# MKV10Z7 register map
Vendor: Freescale Semiconductor, Inc.; Series: Kinetis_V; File version: 1.6
CPU: CM0PLUS r0p0, little endian, no MPU, no FPU, VTOR, 2 interrupt priority bits
Registers are 32-bit, read-write, reset 0x0 unless marked. A register's access mark holds for its fields unless they carry their own. Offsets are from the block's base; [hi:lo] are bit positions; {n}, {i} and the like mark numbered series.

## NVIC — Nested Vectored Interrupt Controller
Base 0xE000E100
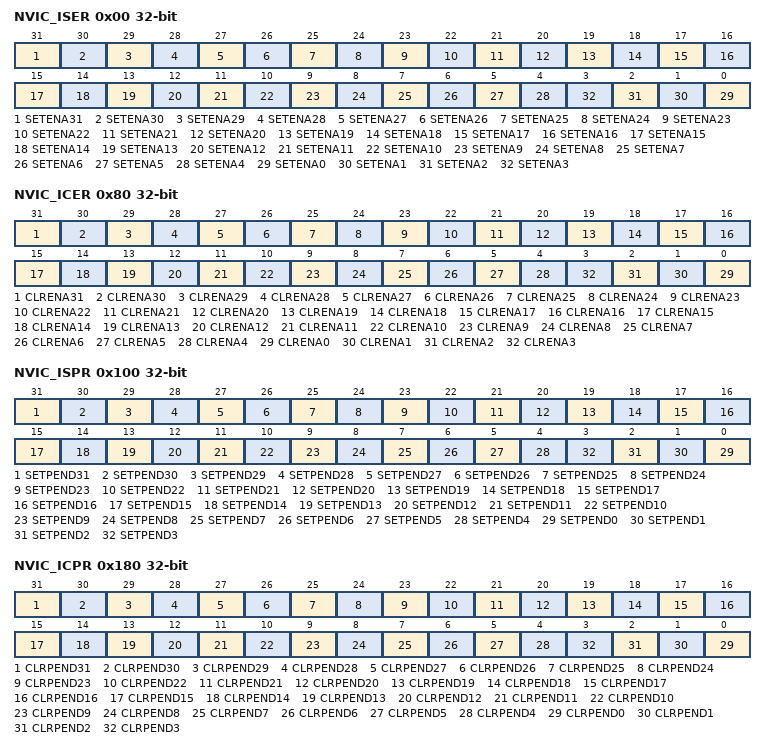
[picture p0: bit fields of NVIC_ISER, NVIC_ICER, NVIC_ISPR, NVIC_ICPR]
0x00 NVIC_ISER — Interrupt Set Enable Register
  [31] SETENA31 — GPIOB, GPIOC, GPIOD and GPIOE Pin detect interrupt set-enable bit
    0=write: no effect; read: GPIOB, GPIOC, GPIOD and GPIOE Pin detect interrupt disabled; 1=write: enable GPIOB, GPIOC, GPIOD and GPIOE Pin detect interrupt; read: GPIOB, GPIOC, GPIOD and GPIOE Pin detect interrupt enabled
  [30] SETENA30 — GPIOA Pin detect interrupt set-enable bit
    0=write: no effect; read: GPIOA Pin detect interrupt disabled; 1=write: enable GPIOA Pin detect interrupt; read: GPIOA Pin detect interrupt enabled
  [29] SETENA29 — Programmable Delay Block interrupt set-enable bit
    0=write: no effect; read: Programmable Delay Block interrupt disabled; 1=write: enable Programmable Delay Block interrupt; read: Programmable Delay Block interrupt enabled
  [28] SETENA28 — Low-Power Timer interrupt set-enable bit
    0=write: no effect; read: Low-Power Timer interrupt disabled; 1=write: enable Low-Power Timer interrupt; read: Low-Power Timer interrupt enabled
  [27] SETENA27 — Multipurpose Clock Generator interrupt set-enable bit
    0=write: no effect; read: Multipurpose Clock Generator interrupt disabled; 1=write: enable Multipurpose Clock Generator interrupt; read: Multipurpose Clock Generator interrupt enabled
  [26] SETENA26 — Reserved iv 42 interrupt set-enable bit
    0=write: no effect; read: Reserved iv 42 interrupt disabled; 1=write: enable Reserved iv 42 interrupt; read: Reserved iv 42 interrupt enabled
  [25] SETENA25 — Digital-to-Analog Converter 0 interrupt set-enable bit
    0=write: no effect; read: Digital-to-Analog Converter 0 interrupt disabled; 1=write: enable Digital-to-Analog Converter 0 interrupt; read: Digital-to-Analog Converter 0 interrupt enabled
  [24] SETENA24 — Reserved iv 40 interrupt set-enable bit
    0=write: no effect; read: Reserved iv 40 interrupt disabled; 1=write: enable Reserved iv 40 interrupt; read: Reserved iv 40 interrupt enabled
  [23] SETENA23 — WDOG and EWM interrupt set-enable bit
    0=write: no effect; read: WDOG and EWM interrupt disabled; 1=write: enable WDOG and EWM interrupt; read: WDOG and EWM interrupt enabled
  [22] SETENA22 — Reserved iv 38 interrupt set-enable bit
    0=write: no effect; read: Reserved iv 38 interrupt disabled; 1=write: enable Reserved iv 38 interrupt; read: Reserved iv 38 interrupt enabled
  [21] SETENA21 — Comparator 1 interrupt set-enable bit
    0=write: no effect; read: Comparator 1 interrupt disabled; 1=write: enable Comparator 1 interrupt; read: Comparator 1 interrupt enabled
  [20] SETENA20 — Comparator 0 interrupt set-enable bit
    0=write: no effect; read: Comparator 0 interrupt disabled; 1=write: enable Comparator 0 interrupt; read: Comparator 0 interrupt enabled
  [19] SETENA19 — FlexTimer Module 2 interrupt set-enable bit
    0=write: no effect; read: FlexTimer Module 2 interrupt disabled; 1=write: enable FlexTimer Module 2 interrupt; read: FlexTimer Module 2 interrupt enabled
  [18] SETENA18 — FlexTimer Module 1 interrupt set-enable bit
    0=write: no effect; read: FlexTimer Module 1 interrupt disabled; 1=write: enable FlexTimer Module 1 interrupt; read: FlexTimer Module 1 interrupt enabled
  [17] SETENA17 — FlexTimer Module 0 interrupt set-enable bit
    0=write: no effect; read: FlexTimer Module 0 interrupt disabled; 1=write: enable FlexTimer Module 0 interrupt; read: FlexTimer Module 0 interrupt enabled
  [16] SETENA16 — Analog-to-Digital Converter 1 interrupt set-enable bit
    0=write: no effect; read: Analog-to-Digital Converter 1 interrupt disabled; 1=write: enable Analog-to-Digital Converter 1 interrupt; read: Analog-to-Digital Converter 1 interrupt enabled
  [15] SETENA15 — Analog-to-Digital Converter 0 interrupt set-enable bit
    0=write: no effect; read: Analog-to-Digital Converter 0 interrupt disabled; 1=write: enable Analog-to-Digital Converter 0 interrupt; read: Analog-to-Digital Converter 0 interrupt enabled
  [14] SETENA14 — Reserved iv 30 interrupt set-enable bit
    0=write: no effect; read: Reserved iv 30 interrupt disabled; 1=write: enable Reserved iv 30 interrupt; read: Reserved iv 30 interrupt enabled
  [13] SETENA13 — UART1 status and error interrupt set-enable bit
    0=write: no effect; read: UART1 status and error interrupt disabled; 1=write: enable UART1 status and error interrupt; read: UART1 status and error interrupt enabled
  [12] SETENA12 — UART0 status and error interrupt set-enable bit
    0=write: no effect; read: UART0 status and error interrupt disabled; 1=write: enable UART0 status and error interrupt; read: UART0 status and error interrupt enabled
  [11] SETENA11 — Reserved iv 27 interrupt set-enable bit
    0=write: no effect; read: Reserved iv 27 interrupt disabled; 1=write: enable Reserved iv 27 interrupt; read: Reserved iv 27 interrupt enabled
  [10] SETENA10 — Serial Peripheral Interface 0 interrupt set-enable bit
    0=write: no effect; read: Serial Peripheral Interface 0 interrupt disabled; 1=write: enable Serial Peripheral Interface 0 interrupt; read: Serial Peripheral Interface 0 interrupt enabled
  [9] SETENA9 — Reserved iv 25 interrupt set-enable bit
    0=write: no effect; read: Reserved iv 25 interrupt disabled; 1=write: enable Reserved iv 25 interrupt; read: Reserved iv 25 interrupt enabled
  [8] SETENA8 — Inter-Integrated Circuit 0 interrupt set-enable bit
    0=write: no effect; read: Inter-Integrated Circuit 0 interrupt disabled; 1=write: enable Inter-Integrated Circuit 0 interrupt; read: Inter-Integrated Circuit 0 interrupt enabled
  [7] SETENA7 — Low Leakage Wakeup interrupt set-enable bit
    0=write: no effect; read: Low Leakage Wakeup interrupt disabled; 1=write: enable Low Leakage Wakeup interrupt; read: Low Leakage Wakeup interrupt enabled
  [6] SETENA6 — Low-voltage detect, low-voltage warning interrupt set-enable bit
    0=write: no effect; read: Low-voltage detect, low-voltage warning interrupt disabled; 1=write: enable Low-voltage detect, low-voltage warning interrupt; read: Low-voltage detect, low-voltage warning interrupt enabled
  [5] SETENA5 — Command complete and read collision interrupt set-enable bit
    0=write: no effect; read: Command complete and read collision interrupt disabled; 1=write: enable Command complete and read collision interrupt; read: Command complete and read collision interrupt enabled
  [4] SETENA4 — DMA channel 0 1 2 3 error interrupt set-enable bit
    0=write: no effect; read: DMA channel 0 1 2 3 error interrupt disabled; 1=write: enable DMA channel 0 1 2 3 error interrupt; read: DMA channel 0 1 2 3 error interrupt enabled
  [n] SETENA{n} (n=0..3) — DMA channel {n} transfer complete interrupt set-enable bit
    0=write: no effect; read: DMA channel {n} transfer complete interrupt disabled; 1=write: enable DMA channel {n} transfer complete interrupt; read: DMA channel {n} transfer complete interrupt enabled
0x80 NVIC_ICER — Interrupt Clear Enable Register
  [31] CLRENA31 — GPIOB, GPIOC, GPIOD and GPIOE Pin detect interrupt clear-enable bit
    0=write: no effect; read: GPIOB, GPIOC, GPIOD and GPIOE Pin detect interrupt disabled; 1=write: disable GPIOB, GPIOC, GPIOD and GPIOE Pin detect interrupt; read: GPIOB, GPIOC, GPIOD and GPIOE Pin detect interrupt enabled
  [30] CLRENA30 — GPIOA Pin detect interrupt clear-enable bit
    0=write: no effect; read: GPIOA Pin detect interrupt disabled; 1=write: disable GPIOA Pin detect interrupt; read: GPIOA Pin detect interrupt enabled
  [29] CLRENA29 — Programmable Delay Block interrupt clear-enable bit
    0=write: no effect; read: Programmable Delay Block interrupt disabled; 1=write: disable Programmable Delay Block interrupt; read: Programmable Delay Block interrupt enabled
  [28] CLRENA28 — Low-Power Timer interrupt clear-enable bit
    0=write: no effect; read: Low-Power Timer interrupt disabled; 1=write: disable Low-Power Timer interrupt; read: Low-Power Timer interrupt enabled
  [27] CLRENA27 — Multipurpose Clock Generator interrupt clear-enable bit
    0=write: no effect; read: Multipurpose Clock Generator interrupt disabled; 1=write: disable Multipurpose Clock Generator interrupt; read: Multipurpose Clock Generator interrupt enabled
  [26] CLRENA26 — Reserved iv 42 interrupt clear-enable bit
    0=write: no effect; read: Reserved iv 42 interrupt disabled; 1=write: disable Reserved iv 42 interrupt; read: Reserved iv 42 interrupt enabled
  [25] CLRENA25 — Digital-to-Analog Converter 0 interrupt clear-enable bit
    0=write: no effect; read: Digital-to-Analog Converter 0 interrupt disabled; 1=write: disable Digital-to-Analog Converter 0 interrupt; read: Digital-to-Analog Converter 0 interrupt enabled
  [24] CLRENA24 — Reserved iv 40 interrupt clear-enable bit
    0=write: no effect; read: Reserved iv 40 interrupt disabled; 1=write: disable Reserved iv 40 interrupt; read: Reserved iv 40 interrupt enabled
  [23] CLRENA23 — WDOG and EWM interrupt clear-enable bit
    0=write: no effect; read: WDOG and EWM interrupt disabled; 1=write: disable WDOG and EWM interrupt; read: WDOG and EWM interrupt enabled
  [22] CLRENA22 — Reserved iv 38 interrupt clear-enable bit
    0=write: no effect; read: Reserved iv 38 interrupt disabled; 1=write: disable Reserved iv 38 interrupt; read: Reserved iv 38 interrupt enabled
  [21] CLRENA21 — Comparator 1 interrupt clear-enable bit
    0=write: no effect; read: Comparator 1 interrupt disabled; 1=write: disable Comparator 1 interrupt; read: Comparator 1 interrupt enabled
  [20] CLRENA20 — Comparator 0 interrupt clear-enable bit
    0=write: no effect; read: Comparator 0 interrupt disabled; 1=write: disable Comparator 0 interrupt; read: Comparator 0 interrupt enabled
  [19] CLRENA19 — FlexTimer Module 2 interrupt clear-enable bit
    0=write: no effect; read: FlexTimer Module 2 interrupt disabled; 1=write: disable FlexTimer Module 2 interrupt; read: FlexTimer Module 2 interrupt enabled
  [18] CLRENA18 — FlexTimer Module 1 interrupt clear-enable bit
    0=write: no effect; read: FlexTimer Module 1 interrupt disabled; 1=write: disable FlexTimer Module 1 interrupt; read: FlexTimer Module 1 interrupt enabled
  [17] CLRENA17 — FlexTimer Module 0 interrupt clear-enable bit
    0=write: no effect; read: FlexTimer Module 0 interrupt disabled; 1=write: disable FlexTimer Module 0 interrupt; read: FlexTimer Module 0 interrupt enabled
  [16] CLRENA16 — Analog-to-Digital Converter 1 interrupt clear-enable bit
    0=write: no effect; read: Analog-to-Digital Converter 1 interrupt disabled; 1=write: disable Analog-to-Digital Converter 1 interrupt; read: Analog-to-Digital Converter 1 interrupt enabled
  [15] CLRENA15 — Analog-to-Digital Converter 0 interrupt clear-enable bit
    0=write: no effect; read: Analog-to-Digital Converter 0 interrupt disabled; 1=write: disable Analog-to-Digital Converter 0 interrupt; read: Analog-to-Digital Converter 0 interrupt enabled
  [14] CLRENA14 — Reserved iv 30 interrupt clear-enable bit
    0=write: no effect; read: Reserved iv 30 interrupt disabled; 1=write: disable Reserved iv 30 interrupt; read: Reserved iv 30 interrupt enabled
  [13] CLRENA13 — UART1 status and error interrupt clear-enable bit
    0=write: no effect; read: UART1 status and error interrupt disabled; 1=write: disable UART1 status and error interrupt; read: UART1 status and error interrupt enabled
  [12] CLRENA12 — UART0 status and error interrupt clear-enable bit
    0=write: no effect; read: UART0 status and error interrupt disabled; 1=write: disable UART0 status and error interrupt; read: UART0 status and error interrupt enabled
  [11] CLRENA11 — Reserved iv 27 interrupt clear-enable bit
    0=write: no effect; read: Reserved iv 27 interrupt disabled; 1=write: disable Reserved iv 27 interrupt; read: Reserved iv 27 interrupt enabled
  [10] CLRENA10 — Serial Peripheral Interface 0 interrupt clear-enable bit
    0=write: no effect; read: Serial Peripheral Interface 0 interrupt disabled; 1=write: disable Serial Peripheral Interface 0 interrupt; read: Serial Peripheral Interface 0 interrupt enabled
  [9] CLRENA9 — Reserved iv 25 interrupt clear-enable bit
    0=write: no effect; read: Reserved iv 25 interrupt disabled; 1=write: disable Reserved iv 25 interrupt; read: Reserved iv 25 interrupt enabled
  [8] CLRENA8 — Inter-Integrated Circuit 0 interrupt clear-enable bit
    0=write: no effect; read: Inter-Integrated Circuit 0 interrupt disabled; 1=write: disable Inter-Integrated Circuit 0 interrupt; read: Inter-Integrated Circuit 0 interrupt enabled
  [7] CLRENA7 — Low Leakage Wakeup interrupt clear-enable bit
    0=write: no effect; read: Low Leakage Wakeup interrupt disabled; 1=write: disable Low Leakage Wakeup interrupt; read: Low Leakage Wakeup interrupt enabled
  [6] CLRENA6 — Low-voltage detect, low-voltage warning interrupt clear-enable bit
    0=write: no effect; read: Low-voltage detect, low-voltage warning interrupt disabled; 1=write: disable Low-voltage detect, low-voltage warning interrupt; read: Low-voltage detect, low-voltage warning interrupt enabled
  [5] CLRENA5 — Command complete and read collision interrupt clear-enable bit
    0=write: no effect; read: Command complete and read collision interrupt disabled; 1=write: disable Command complete and read collision interrupt; read: Command complete and read collision interrupt enabled
  [4] CLRENA4 — DMA channel 0 1 2 3 error interrupt clear-enable bit
    0=write: no effect; read: DMA channel 0 1 2 3 error interrupt disabled; 1=write: disable DMA channel 0 1 2 3 error interrupt; read: DMA channel 0 1 2 3 error interrupt enabled
  [n] CLRENA{n} (n=0..3) — DMA channel {n} transfer complete interrupt clear-enable bit
    0=write: no effect; read: DMA channel {n} transfer complete interrupt disabled; 1=write: disable DMA channel {n} transfer complete interrupt; read: DMA channel {n} transfer complete interrupt enabled
0x100 NVIC_ISPR — Interrupt Set Pending Register
  [31] SETPEND31 — GPIOB, GPIOC, GPIOD and GPIOE Pin detect interrupt set-pending bit
    0=write: no effect; read: GPIOB, GPIOC, GPIOD and GPIOE Pin detect interrupt is not pending; 1=write: changes the GPIOB, GPIOC, GPIOD and GPIOE Pin detect interrupt state to pending; read: GPIOB, GPIOC, GPIOD and GPIOE Pin detect interrupt is pending
  [30] SETPEND30 — GPIOA Pin detect interrupt set-pending bit
    0=write: no effect; read: GPIOA Pin detect interrupt is not pending; 1=write: changes the GPIOA Pin detect interrupt state to pending; read: GPIOA Pin detect interrupt is pending
  [29] SETPEND29 — Programmable Delay Block interrupt set-pending bit
    0=write: no effect; read: Programmable Delay Block interrupt is not pending; 1=write: changes the Programmable Delay Block interrupt state to pending; read: Programmable Delay Block interrupt is pending
  [28] SETPEND28 — Low-Power Timer interrupt set-pending bit
    0=write: no effect; read: Low-Power Timer interrupt is not pending; 1=write: changes the Low-Power Timer interrupt state to pending; read: Low-Power Timer interrupt is pending
  [27] SETPEND27 — Multipurpose Clock Generator interrupt set-pending bit
    0=write: no effect; read: Multipurpose Clock Generator interrupt is not pending; 1=write: changes the Multipurpose Clock Generator interrupt state to pending; read: Multipurpose Clock Generator interrupt is pending
  [26] SETPEND26 — Reserved iv 42 interrupt set-pending bit
    0=write: no effect; read: Reserved iv 42 interrupt is not pending; 1=write: changes the Reserved iv 42 interrupt state to pending; read: Reserved iv 42 interrupt is pending
  [25] SETPEND25 — Digital-to-Analog Converter 0 interrupt set-pending bit
    0=write: no effect; read: Digital-to-Analog Converter 0 interrupt is not pending; 1=write: changes the Digital-to-Analog Converter 0 interrupt state to pending; read: Digital-to-Analog Converter 0 interrupt is pending
  [24] SETPEND24 — Reserved iv 40 interrupt set-pending bit
    0=write: no effect; read: Reserved iv 40 interrupt is not pending; 1=write: changes the Reserved iv 40 interrupt state to pending; read: Reserved iv 40 interrupt is pending
  [23] SETPEND23 — WDOG and EWM interrupt set-pending bit
    0=write: no effect; read: WDOG and EWM interrupt is not pending; 1=write: changes the WDOG and EWM interrupt state to pending; read: WDOG and EWM interrupt is pending
  [22] SETPEND22 — Reserved iv 38 interrupt set-pending bit
    0=write: no effect; read: Reserved iv 38 interrupt is not pending; 1=write: changes the Reserved iv 38 interrupt state to pending; read: Reserved iv 38 interrupt is pending
  [21] SETPEND21 — Comparator 1 interrupt set-pending bit
    0=write: no effect; read: Comparator 1 interrupt is not pending; 1=write: changes the Comparator 1 interrupt state to pending; read: Comparator 1 interrupt is pending
  [20] SETPEND20 — Comparator 0 interrupt set-pending bit
    0=write: no effect; read: Comparator 0 interrupt is not pending; 1=write: changes the Comparator 0 interrupt state to pending; read: Comparator 0 interrupt is pending
  [19] SETPEND19 — FlexTimer Module 2 interrupt set-pending bit
    0=write: no effect; read: FlexTimer Module 2 interrupt is not pending; 1=write: changes the FlexTimer Module 2 interrupt state to pending; read: FlexTimer Module 2 interrupt is pending
  [18] SETPEND18 — FlexTimer Module 1 interrupt set-pending bit
    0=write: no effect; read: FlexTimer Module 1 interrupt is not pending; 1=write: changes the FlexTimer Module 1 interrupt state to pending; read: FlexTimer Module 1 interrupt is pending
  [17] SETPEND17 — FlexTimer Module 0 interrupt set-pending bit
    0=write: no effect; read: FlexTimer Module 0 interrupt is not pending; 1=write: changes the FlexTimer Module 0 interrupt state to pending; read: FlexTimer Module 0 interrupt is pending
  [16] SETPEND16 — Analog-to-Digital Converter 1 interrupt set-pending bit
    0=write: no effect; read: Analog-to-Digital Converter 1 interrupt is not pending; 1=write: changes the Analog-to-Digital Converter 1 interrupt state to pending; read: Analog-to-Digital Converter 1 interrupt is pending
  [15] SETPEND15 — Analog-to-Digital Converter 0 interrupt set-pending bit
    0=write: no effect; read: Analog-to-Digital Converter 0 interrupt is not pending; 1=write: changes the Analog-to-Digital Converter 0 interrupt state to pending; read: Analog-to-Digital Converter 0 interrupt is pending
  [14] SETPEND14 — Reserved iv 30 interrupt set-pending bit
    0=write: no effect; read: Reserved iv 30 interrupt is not pending; 1=write: changes the Reserved iv 30 interrupt state to pending; read: Reserved iv 30 interrupt is pending
  [13] SETPEND13 — UART1 status and error interrupt set-pending bit
    0=write: no effect; read: UART1 status and error interrupt is not pending; 1=write: changes the UART1 status and error interrupt state to pending; read: UART1 status and error interrupt is pending
  [12] SETPEND12 — UART0 status and error interrupt set-pending bit
    0=write: no effect; read: UART0 status and error interrupt is not pending; 1=write: changes the UART0 status and error interrupt state to pending; read: UART0 status and error interrupt is pending
  [11] SETPEND11 — Reserved iv 27 interrupt set-pending bit
    0=write: no effect; read: Reserved iv 27 interrupt is not pending; 1=write: changes the Reserved iv 27 interrupt state to pending; read: Reserved iv 27 interrupt is pending
  [10] SETPEND10 — Serial Peripheral Interface 0 interrupt set-pending bit
    0=write: no effect; read: Serial Peripheral Interface 0 interrupt is not pending; 1=write: changes the Serial Peripheral Interface 0 interrupt state to pending; read: Serial Peripheral Interface 0 interrupt is pending
  [9] SETPEND9 — Reserved iv 25 interrupt set-pending bit
    0=write: no effect; read: Reserved iv 25 interrupt is not pending; 1=write: changes the Reserved iv 25 interrupt state to pending; read: Reserved iv 25 interrupt is pending
  [8] SETPEND8 — Inter-Integrated Circuit 0 interrupt set-pending bit
    0=write: no effect; read: Inter-Integrated Circuit 0 interrupt is not pending; 1=write: changes the Inter-Integrated Circuit 0 interrupt state to pending; read: Inter-Integrated Circuit 0 interrupt is pending
  [7] SETPEND7 — Low Leakage Wakeup interrupt set-pending bit
    0=write: no effect; read: Low Leakage Wakeup interrupt is not pending; 1=write: changes the Low Leakage Wakeup interrupt state to pending; read: Low Leakage Wakeup interrupt is pending
  [6] SETPEND6 — Low-voltage detect, low-voltage warning interrupt set-pending bit
    0=write: no effect; read: Low-voltage detect, low-voltage warning interrupt is not pending; 1=write: changes the Low-voltage detect, low-voltage warning interrupt state to pending; read: Low-voltage detect, low-voltage warning interrupt is pending
  [5] SETPEND5 — Command complete and read collision interrupt set-pending bit
    0=write: no effect; read: Command complete and read collision interrupt is not pending; 1=write: changes the Command complete and read collision interrupt state to pending; read: Command complete and read collision interrupt is pending
  [4] SETPEND4 — DMA channel 0 1 2 3 error interrupt set-pending bit
    0=write: no effect; read: DMA channel 0 1 2 3 error interrupt is not pending; 1=write: changes the DMA channel 0 1 2 3 error interrupt state to pending; read: DMA channel 0 1 2 3 error interrupt is pending
  [n] SETPEND{n} (n=0..3) — DMA channel {n} transfer complete interrupt set-pending bit
    0=write: no effect; read: DMA channel {n} transfer complete interrupt is not pending; 1=write: changes the DMA channel {n} transfer complete interrupt state to pending; read: DMA channel {n} transfer complete interrupt is pending
0x180 NVIC_ICPR — Interrupt Clear Pending Register
  [31] CLRPEND31 — GPIOB, GPIOC, GPIOD and GPIOE Pin detect interrupt clear-pending bit
    0=write: no effect; read: GPIOB, GPIOC, GPIOD and GPIOE Pin detect interrupt is not pending; 1=write: removes pending state from the GPIOB, GPIOC, GPIOD and GPIOE Pin detect interrupt; read: GPIOB, GPIOC, GPIOD and GPIOE Pin detect interrupt is pending
  [30] CLRPEND30 — GPIOA Pin detect interrupt clear-pending bit
    0=write: no effect; read: GPIOA Pin detect interrupt is not pending; 1=write: removes pending state from the GPIOA Pin detect interrupt; read: GPIOA Pin detect interrupt is pending
  [29] CLRPEND29 — Programmable Delay Block interrupt clear-pending bit
    0=write: no effect; read: Programmable Delay Block interrupt is not pending; 1=write: removes pending state from the Programmable Delay Block interrupt; read: Programmable Delay Block interrupt is pending
  [28] CLRPEND28 — Low-Power Timer interrupt clear-pending bit
    0=write: no effect; read: Low-Power Timer interrupt is not pending; 1=write: removes pending state from the Low-Power Timer interrupt; read: Low-Power Timer interrupt is pending
  [27] CLRPEND27 — Multipurpose Clock Generator interrupt clear-pending bit
    0=write: no effect; read: Multipurpose Clock Generator interrupt is not pending; 1=write: removes pending state from the Multipurpose Clock Generator interrupt; read: Multipurpose Clock Generator interrupt is pending
  [26] CLRPEND26 — Reserved iv 42 interrupt clear-pending bit
    0=write: no effect; read: Reserved iv 42 interrupt is not pending; 1=write: removes pending state from the Reserved iv 42 interrupt; read: Reserved iv 42 interrupt is pending
  [25] CLRPEND25 — Digital-to-Analog Converter 0 interrupt clear-pending bit
    0=write: no effect; read: Digital-to-Analog Converter 0 interrupt is not pending; 1=write: removes pending state from the Digital-to-Analog Converter 0 interrupt; read: Digital-to-Analog Converter 0 interrupt is pending
  [24] CLRPEND24 — Reserved iv 40 interrupt clear-pending bit
    0=write: no effect; read: Reserved iv 40 interrupt is not pending; 1=write: removes pending state from the Reserved iv 40 interrupt; read: Reserved iv 40 interrupt is pending
  [23] CLRPEND23 — WDOG and EWM interrupt clear-pending bit
    0=write: no effect; read: WDOG and EWM interrupt is not pending; 1=write: removes pending state from the WDOG and EWM interrupt; read: WDOG and EWM interrupt is pending
  [22] CLRPEND22 — Reserved iv 38 interrupt clear-pending bit
    0=write: no effect; read: Reserved iv 38 interrupt is not pending; 1=write: removes pending state from the Reserved iv 38 interrupt; read: Reserved iv 38 interrupt is pending
  [21] CLRPEND21 — Comparator 1 interrupt clear-pending bit
    0=write: no effect; read: Comparator 1 interrupt is not pending; 1=write: removes pending state from the Comparator 1 interrupt; read: Comparator 1 interrupt is pending
  [20] CLRPEND20 — Comparator 0 interrupt clear-pending bit
    0=write: no effect; read: Comparator 0 interrupt is not pending; 1=write: removes pending state from the Comparator 0 interrupt; read: Comparator 0 interrupt is pending
  [19] CLRPEND19 — FlexTimer Module 2 interrupt clear-pending bit
    0=write: no effect; read: FlexTimer Module 2 interrupt is not pending; 1=write: removes pending state from the FlexTimer Module 2 interrupt; read: FlexTimer Module 2 interrupt is pending
  [18] CLRPEND18 — FlexTimer Module 1 interrupt clear-pending bit
    0=write: no effect; read: FlexTimer Module 1 interrupt is not pending; 1=write: removes pending state from the FlexTimer Module 1 interrupt; read: FlexTimer Module 1 interrupt is pending
  [17] CLRPEND17 — FlexTimer Module 0 interrupt clear-pending bit
    0=write: no effect; read: FlexTimer Module 0 interrupt is not pending; 1=write: removes pending state from the FlexTimer Module 0 interrupt; read: FlexTimer Module 0 interrupt is pending
  [16] CLRPEND16 — Analog-to-Digital Converter 1 interrupt clear-pending bit
    0=write: no effect; read: Analog-to-Digital Converter 1 interrupt is not pending; 1=write: removes pending state from the Analog-to-Digital Converter 1 interrupt; read: Analog-to-Digital Converter 1 interrupt is pending
  [15] CLRPEND15 — Analog-to-Digital Converter 0 interrupt clear-pending bit
    0=write: no effect; read: Analog-to-Digital Converter 0 interrupt is not pending; 1=write: removes pending state from the Analog-to-Digital Converter 0 interrupt; read: Analog-to-Digital Converter 0 interrupt is pending
  [14] CLRPEND14 — Reserved iv 30 interrupt clear-pending bit
    0=write: no effect; read: Reserved iv 30 interrupt is not pending; 1=write: removes pending state from the Reserved iv 30 interrupt; read: Reserved iv 30 interrupt is pending
  [13] CLRPEND13 — UART1 status and error interrupt clear-pending bit
    0=write: no effect; read: UART1 status and error interrupt is not pending; 1=write: removes pending state from the UART1 status and error interrupt; read: UART1 status and error interrupt is pending
  [12] CLRPEND12 — UART0 status and error interrupt clear-pending bit
    0=write: no effect; read: UART0 status and error interrupt is not pending; 1=write: removes pending state from the UART0 status and error interrupt; read: UART0 status and error interrupt is pending
  [11] CLRPEND11 — Reserved iv 27 interrupt clear-pending bit
    0=write: no effect; read: Reserved iv 27 interrupt is not pending; 1=write: removes pending state from the Reserved iv 27 interrupt; read: Reserved iv 27 interrupt is pending
  [10] CLRPEND10 — Serial Peripheral Interface 0 interrupt clear-pending bit
    0=write: no effect; read: Serial Peripheral Interface 0 interrupt is not pending; 1=write: removes pending state from the Serial Peripheral Interface 0 interrupt; read: Serial Peripheral Interface 0 interrupt is pending
  [9] CLRPEND9 — Reserved iv 25 interrupt clear-pending bit
    0=write: no effect; read: Reserved iv 25 interrupt is not pending; 1=write: removes pending state from the Reserved iv 25 interrupt; read: Reserved iv 25 interrupt is pending
  [8] CLRPEND8 — Inter-Integrated Circuit 0 interrupt clear-pending bit
    0=write: no effect; read: Inter-Integrated Circuit 0 interrupt is not pending; 1=write: removes pending state from the Inter-Integrated Circuit 0 interrupt; read: Inter-Integrated Circuit 0 interrupt is pending
  [7] CLRPEND7 — Low Leakage Wakeup interrupt clear-pending bit
    0=write: no effect; read: Low Leakage Wakeup interrupt is not pending; 1=write: removes pending state from the Low Leakage Wakeup interrupt; read: Low Leakage Wakeup interrupt is pending
  [6] CLRPEND6 — Low-voltage detect, low-voltage warning interrupt clear-pending bit
    0=write: no effect; read: Low-voltage detect, low-voltage warning interrupt is not pending; 1=write: removes pending state from the Low-voltage detect, low-voltage warning interrupt; read: Low-voltage detect, low-voltage warning interrupt is pending
  [5] CLRPEND5 — Command complete and read collision interrupt clear-pending bit
    0=write: no effect; read: Command complete and read collision interrupt is not pending; 1=write: removes pending state from the Command complete and read collision interrupt; read: Command complete and read collision interrupt is pending
  [4] CLRPEND4 — DMA channel 0 1 2 3 error interrupt clear-pending bit
    0=write: no effect; read: DMA channel 0 1 2 3 error interrupt is not pending; 1=write: removes pending state from the DMA channel 0 1 2 3 error interrupt; read: DMA channel 0 1 2 3 error interrupt is pending
  [n] CLRPEND{n} (n=0..3) — DMA channel {n} transfer complete interrupt clear-pending bit
    0=write: no effect; read: DMA channel {n} transfer complete interrupt is not pending; 1=write: removes pending state from the DMA channel {n} transfer complete interrupt; read: DMA channel {n} transfer complete interrupt is pending
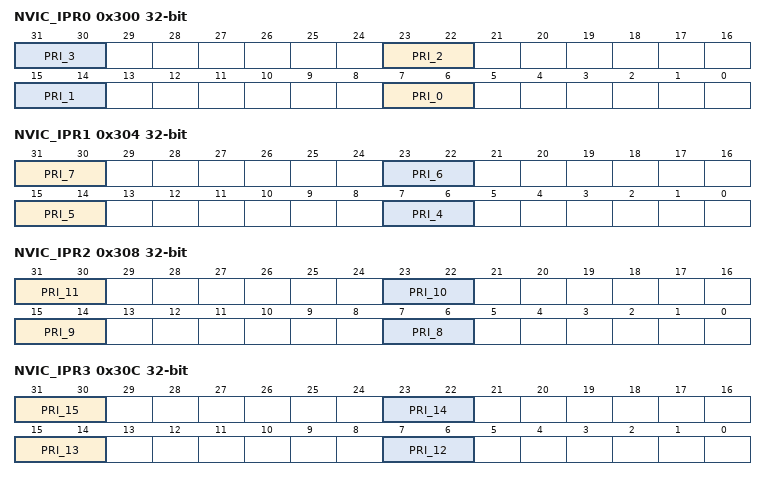
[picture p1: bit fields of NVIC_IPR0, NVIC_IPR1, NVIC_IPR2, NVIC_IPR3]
0x300 NVIC_IPR0 — Interrupt Priority Register 0
  [8n+7:8n+6] PRI_{n} (n=0..3) — Priority of the DMA channel {n} transfer complete interrupt
0x304 NVIC_IPR1 — Interrupt Priority Register 1
  [31:30] PRI_7 — Priority of the Low Leakage Wakeup interrupt
  [23:22] PRI_6 — Priority of the Low-voltage detect, low-voltage warning interrupt
  [15:14] PRI_5 — Priority of the Command complete and read collision interrupt
  [7:6] PRI_4 — Priority of the DMA channel 0 1 2 3 error interrupt
0x308 NVIC_IPR2 — Interrupt Priority Register 2
  [31:30] PRI_11 — Priority of the Reserved iv 27 interrupt
  [23:22] PRI_10 — Priority of the Serial Peripheral Interface 0 interrupt
  [15:14] PRI_9 — Priority of the Reserved iv 25 interrupt
  [7:6] PRI_8 — Priority of the Inter-Integrated Circuit 0 interrupt
0x30C NVIC_IPR3 — Interrupt Priority Register 3
  [31:30] PRI_15 — Priority of the Analog-to-Digital Converter 0 interrupt
  [23:22] PRI_14 — Priority of the Reserved iv 30 interrupt
  [15:14] PRI_13 — Priority of the UART1 status and error interrupt
  [7:6] PRI_12 — Priority of the UART0 status and error interrupt
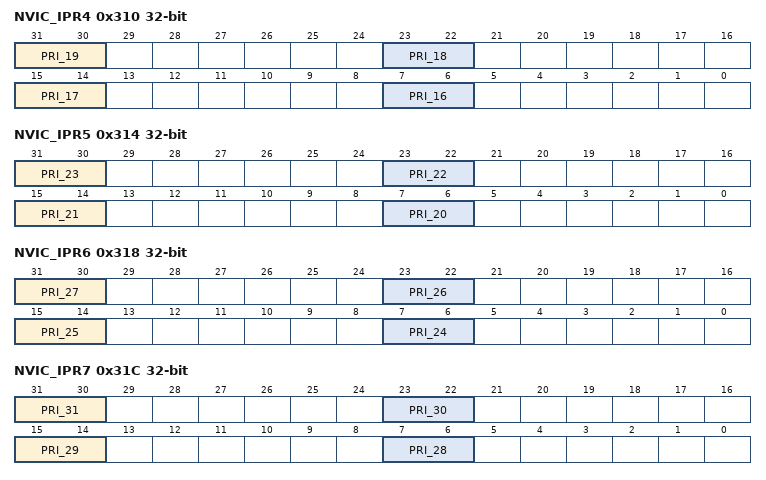
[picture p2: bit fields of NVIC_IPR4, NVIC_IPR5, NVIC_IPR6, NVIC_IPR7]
0x310 NVIC_IPR4 — Interrupt Priority Register 4
  [31:30] PRI_19 — Priority of the FlexTimer Module 2 interrupt
  [23:22] PRI_18 — Priority of the FlexTimer Module 1 interrupt
  [15:14] PRI_17 — Priority of the FlexTimer Module 0 interrupt
  [7:6] PRI_16 — Priority of the Analog-to-Digital Converter 1 interrupt
0x314 NVIC_IPR5 — Interrupt Priority Register 5
  [31:30] PRI_23 — Priority of the WDOG and EWM interrupt
  [23:22] PRI_22 — Priority of the Reserved iv 38 interrupt
  [15:14] PRI_21 — Priority of the Comparator 1 interrupt
  [7:6] PRI_20 — Priority of the Comparator 0 interrupt
0x318 NVIC_IPR6 — Interrupt Priority Register 6
  [31:30] PRI_27 — Priority of the Multipurpose Clock Generator interrupt
  [23:22] PRI_26 — Priority of the Reserved iv 42 interrupt
  [15:14] PRI_25 — Priority of the Digital-to-Analog Converter 0 interrupt
  [7:6] PRI_24 — Priority of the Reserved iv 40 interrupt
0x31C NVIC_IPR7 — Interrupt Priority Register 7
  [31:30] PRI_31 — Priority of the GPIOB, GPIOC, GPIOD and GPIOE Pin detect interrupt
  [23:22] PRI_30 — Priority of the GPIOA Pin detect interrupt
  [15:14] PRI_29 — Priority of the Programmable Delay Block interrupt
  [7:6] PRI_28 — Priority of the Low-Power Timer interrupt
